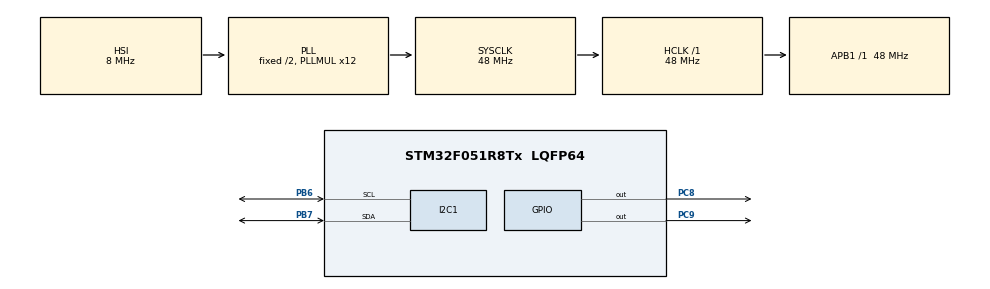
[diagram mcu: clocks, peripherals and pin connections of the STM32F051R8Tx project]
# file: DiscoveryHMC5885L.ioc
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Mcu.Family=STM32F0
Mcu.Name=STM32F051R8Tx
Mcu.Package=LQFP64
PB6.Mode=I2C
PB6.Signal=I2C1_SCL
PB7.Mode=I2C
PB7.Signal=I2C1_SDA
PC8.Signal=GPIO_Output
PC9.Signal=GPIO_Output
PF0-OSC_IN.Mode=HSE-External-Oscillator
PF0-OSC_IN.Signal=RCC_OSC_IN
PF1-OSC_OUT.Mode=HSE-External-Oscillator
PF1-OSC_OUT.Signal=RCC_OSC_OUT
ProjectManager.HeapSize=0x200
ProjectManager.StackSize=0x400
ProjectManager.TargetToolchain=TrueSTUDIO
RCC.AHBFreq_Value=48000000
RCC.APB1Freq_Value=48000000
RCC.APB1TimFreq_Value=48000000
RCC.HCLKFreq_Value=48000000
RCC.PLLMUL=RCC_PLL_MUL12
RCC.SYSCLKFreq_VALUE=48000000
RCC.SYSCLKSource=RCC_SYSCLKSOURCE_PLLCLK
board=custom

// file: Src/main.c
/**
  ******************************************************************************
  * @file           : main.c
  * @brief          : Main program body
  ******************************************************************************
  ** This notice applies to any and all portions of this file
  * that are not between comment pairs USER CODE BEGIN and
  * USER CODE END. Other portions of this file, whether
  * inserted by the user or by software development tools
  * are owned by their respective copyright owners.
  *
  * COPYRIGHT(c) 2018 STMicroelectronics
  *
  * Redistribution and use in source and binary forms, with or without modification,
  * are permitted provided that the following conditions are met:
  *   1. Redistributions of source code must retain the above copyright notice,
  *      this list of conditions and the following disclaimer.
  *   2. Redistributions in binary form must reproduce the above copyright notice,
  *      this list of conditions and the following disclaimer in the documentation
  *      and/or other materials provided with the distribution.
  *   3. Neither the name of STMicroelectronics nor the names of its contributors
  *      may be used to endorse or promote products derived from this software
  *      without specific prior written permission.
  *
  * THIS SOFTWARE IS PROVIDED BY THE COPYRIGHT HOLDERS AND CONTRIBUTORS "AS IS"
  * AND ANY EXPRESS OR IMPLIED WARRANTIES, INCLUDING, BUT NOT LIMITED TO, THE
  * IMPLIED WARRANTIES OF MERCHANTABILITY AND FITNESS FOR A PARTICULAR PURPOSE ARE
  * DISCLAIMED. IN NO EVENT SHALL THE COPYRIGHT HOLDER OR CONTRIBUTORS BE LIABLE
  * FOR ANY DIRECT, INDIRECT, INCIDENTAL, SPECIAL, EXEMPLARY, OR CONSEQUENTIAL
  * DAMAGES (INCLUDING, BUT NOT LIMITED TO, PROCUREMENT OF SUBSTITUTE GOODS OR
  * SERVICES; LOSS OF USE, DATA, OR PROFITS; OR BUSINESS INTERRUPTION) HOWEVER
  * CAUSED AND ON ANY THEORY OF LIABILITY, WHETHER IN CONTRACT, STRICT LIABILITY,
  * OR TORT (INCLUDING NEGLIGENCE OR OTHERWISE) ARISING IN ANY WAY OUT OF THE USE
  * OF THIS SOFTWARE, EVEN IF ADVISED OF THE POSSIBILITY OF SUCH DAMAGE.
  *
  ******************************************************************************
  */
#include "main.h"
#include "stm32f0xx_hal.h"
#include "HMC5883L.h"

I2C_HandleTypeDef hi2c1;

/* USER CODE BEGIN PV */
/* Private variables ---------------------------------------------------------*/

/* USER CODE END PV */

void SystemClock_Config(void);
static void MX_GPIO_Init(void);
static void MX_I2C1_Init(void);
void HMC5883LRead(void);
void setGain(hmc5883MagGain gain);
void tiltCompensatedAngle(void);
void HMC5883LInit(void);

/* USER CODE BEGIN PFP */
/* Private function prototypes -----------------------------------------------*/
	static float Gauss_LSB_XY = 1100.0F;
	static float Gauss_LSB_Z  = 980.0F;

	float X,Y,Z,mX,mY,mZ;
	uint8_t regAddress=0x00;
	uint8_t data[8];
	uint16_t devAddress=0x1B;
	float declinationAngle, headingDegrees,heading;

/* USER CODE END PFP */

int main(void)
{

  /* MCU Configuration----------------------------------------------------------*/

  /* Reset of all peripherals, Initializes the Flash interface and the Systick. */
   HAL_Init();

  /* Configure the system clock */
  SystemClock_Config();

  /* Initialize all configured peripherals */
  MX_GPIO_Init();
  MX_I2C1_Init();
  HMC5883LInit();

  /* Infinite loop */
  /* USER CODE BEGIN WHILE */
  while (1)
  {
	  tiltCompensatedAngle();

  }

}
void HMC5883LInit(void)
{
		data[0]=0x0B;
	    data[1]=0x01;
	  	HAL_I2C_Master_Transmit(&hi2c1,devAddress,data,2,1000);

	  	HAL_Delay(100);

	  	data[0]=0x09;
	    data[1]=0x1D;
	    HAL_I2C_Master_Transmit(&hi2c1,devAddress,data,2,1000);

	    HAL_Delay(100);
}
void HMC5883LRead(void)
{
	 	  HAL_I2C_Master_Transmit(&hi2c1,devAddress,&regAddress,1,1000);
		  HAL_I2C_Master_Receive(&hi2c1,devAddress,data,6,1000);

		  	  X = (int16_t)(data[0] | ((int16_t)data[1] << 8));
		  	  Y = (int16_t)(data[2] | ((int16_t)data[3] << 8));
		  	  Z = (int16_t)(data[4] | ((int16_t)data[5] << 8));

		  	//Hesapla (manyetik vektör deðerleri mikro Tesla (uT) cinsindendir)
			     mX = X / Gauss_LSB_XY * GAUSS_TO_MICROTESLA;
			     mY = Y / Gauss_LSB_XY * GAUSS_TO_MICROTESLA;
			     mZ = Z / Gauss_LSB_Z  * GAUSS_TO_MICROTESLA;

}

void setGain(hmc5883MagGain gain)
{
	switch(gain)
	  {
	    case HMC5883_MAGGAIN_1_3:
	      Gauss_LSB_XY = 1100;
	      Gauss_LSB_Z  = 980;
	      break;
	    case HMC5883_MAGGAIN_1_9:
	      Gauss_LSB_XY = 855;
	      Gauss_LSB_Z  = 760;
	      break;
	    case HMC5883_MAGGAIN_2_5:
	      Gauss_LSB_XY = 670;
	      Gauss_LSB_Z  = 600;
	      break;
	    case HMC5883_MAGGAIN_4_0:
	      Gauss_LSB_XY = 450;
	      Gauss_LSB_Z  = 400;
	      break;
	    case HMC5883_MAGGAIN_4_7:
	      Gauss_LSB_XY = 400;
	      Gauss_LSB_Z  = 255;
	      break;
	    case HMC5883_MAGGAIN_5_6:
	      Gauss_LSB_XY = 330;
	      Gauss_LSB_Z  = 295;
	      break;
	    case HMC5883_MAGGAIN_8_1:
	      Gauss_LSB_XY = 230;
	      Gauss_LSB_Z  = 205;
	      break;
	  }
}

void tiltCompensatedAngle(void)
{
	setGain(HMC5883_MAGGAIN_1_3);
	HMC5883LRead();

	heading=atan2(mY,mX);

	declinationAngle=0.0872;
	heading +=declinationAngle;

	if(heading < 0)
	{
		heading += 2*PI;
	}

	if(heading > PI*2)
	{
		heading -=2*PI;
	}

	headingDegrees = heading *180/PI;

}
void SystemClock_Config(void)
{

  RCC_OscInitTypeDef RCC_OscInitStruct;
  RCC_ClkInitTypeDef RCC_ClkInitStruct;
  RCC_PeriphCLKInitTypeDef PeriphClkInit;

    /**Initializes the CPU, AHB and APB busses clocks
    */
  RCC_OscInitStruct.OscillatorType = RCC_OSCILLATORTYPE_HSI;
  RCC_OscInitStruct.HSIState = RCC_HSI_ON;
  RCC_OscInitStruct.HSICalibrationValue = 16;
  RCC_OscInitStruct.PLL.PLLState = RCC_PLL_ON;
  RCC_OscInitStruct.PLL.PLLSource = RCC_PLLSOURCE_HSI;
  RCC_OscInitStruct.PLL.PLLMUL = RCC_PLL_MUL12;
  RCC_OscInitStruct.PLL.PREDIV = RCC_PREDIV_DIV1;
  if (HAL_RCC_OscConfig(&RCC_OscInitStruct) != HAL_OK)
  {
    _Error_Handler(__FILE__, __LINE__);
  }

    /**Initializes the CPU, AHB and APB busses clocks
    */
  RCC_ClkInitStruct.ClockType = RCC_CLOCKTYPE_HCLK|RCC_CLOCKTYPE_SYSCLK
                              |RCC_CLOCKTYPE_PCLK1;
  RCC_ClkInitStruct.SYSCLKSource = RCC_SYSCLKSOURCE_PLLCLK;
  RCC_ClkInitStruct.AHBCLKDivider = RCC_SYSCLK_DIV1;
  RCC_ClkInitStruct.APB1CLKDivider = RCC_HCLK_DIV1;

  if (HAL_RCC_ClockConfig(&RCC_ClkInitStruct, FLASH_LATENCY_1) != HAL_OK)
  {
    _Error_Handler(__FILE__, __LINE__);
  }

  PeriphClkInit.PeriphClockSelection = RCC_PERIPHCLK_I2C1;
  PeriphClkInit.I2c1ClockSelection = RCC_I2C1CLKSOURCE_HSI;
  if (HAL_RCCEx_PeriphCLKConfig(&PeriphClkInit) != HAL_OK)
  {
    _Error_Handler(__FILE__, __LINE__);
  }

    /**Configure the Systick interrupt time
    */
  HAL_SYSTICK_Config(HAL_RCC_GetHCLKFreq()/1000);

    /**Configure the Systick
    */
  HAL_SYSTICK_CLKSourceConfig(SYSTICK_CLKSOURCE_HCLK);

  /* SysTick_IRQn interrupt configuration */
  HAL_NVIC_SetPriority(SysTick_IRQn, 0, 0);
}

/* I2C1 init function */
static void MX_I2C1_Init(void)
{
  hi2c1.Instance = I2C1;
  hi2c1.Init.Timing = 0x2000090E;
  hi2c1.Init.OwnAddress1 = 0;
  hi2c1.Init.AddressingMode = I2C_ADDRESSINGMODE_7BIT;
  hi2c1.Init.DualAddressMode = I2C_DUALADDRESS_DISABLE;
  hi2c1.Init.OwnAddress2 = 0;
  hi2c1.Init.OwnAddress2Masks = I2C_OA2_NOMASK;
  hi2c1.Init.GeneralCallMode = I2C_GENERALCALL_DISABLE;
  hi2c1.Init.NoStretchMode = I2C_NOSTRETCH_DISABLE;
  if (HAL_I2C_Init(&hi2c1) != HAL_OK)
  {
    _Error_Handler(__FILE__, __LINE__);
  }

    /**Configure Analogue filter
    */
  if (HAL_I2CEx_ConfigAnalogFilter(&hi2c1, I2C_ANALOGFILTER_ENABLE) != HAL_OK)
  {
    _Error_Handler(__FILE__, __LINE__);
  }

    /**Configure Digital filter
    */
  if (HAL_I2CEx_ConfigDigitalFilter(&hi2c1, 0) != HAL_OK)
  {
    _Error_Handler(__FILE__, __LINE__);
  }

}

/** Configure pins as
        * Analog
        * Input
        * Output
        * EVENT_OUT
        * EXTI
*/
static void MX_GPIO_Init(void)
{

  GPIO_InitTypeDef GPIO_InitStruct;

  /* GPIO Ports Clock Enable */
  __HAL_RCC_GPIOF_CLK_ENABLE();
  __HAL_RCC_GPIOC_CLK_ENABLE();
  __HAL_RCC_GPIOB_CLK_ENABLE();

  /*Configure GPIO pin Output Level */
  HAL_GPIO_WritePin(GPIOC, GPIO_PIN_8|GPIO_PIN_9, GPIO_PIN_RESET);

  /*Configure GPIO pins : PC8 PC9 */
  GPIO_InitStruct.Pin = GPIO_PIN_8|GPIO_PIN_9;
  GPIO_InitStruct.Mode = GPIO_MODE_OUTPUT_PP;
  GPIO_InitStruct.Pull = GPIO_NOPULL;
  GPIO_InitStruct.Speed = GPIO_SPEED_FREQ_LOW;
  HAL_GPIO_Init(GPIOC, &GPIO_InitStruct);

}

void _Error_Handler(char *file, int line)
{
  while(1)
  {
  }
}

/************************ (C) COPYRIGHT STMicroelectronics *****END OF FILE****/
